# H6 register map
Vendor: Allwinner; Series: H6; File version: 0.1
CPU: CA53 0, little endian, MPU, no FPU, 0 interrupt priority bits
Registers are 32-bit, read-write, reset 0x0 unless marked. A register's access mark holds for its fields unless they carry their own. Offsets are from the block's base; [hi:lo] are bit positions; {n}, {i} and the like mark numbered series.

## RTC
Base 0x07000000
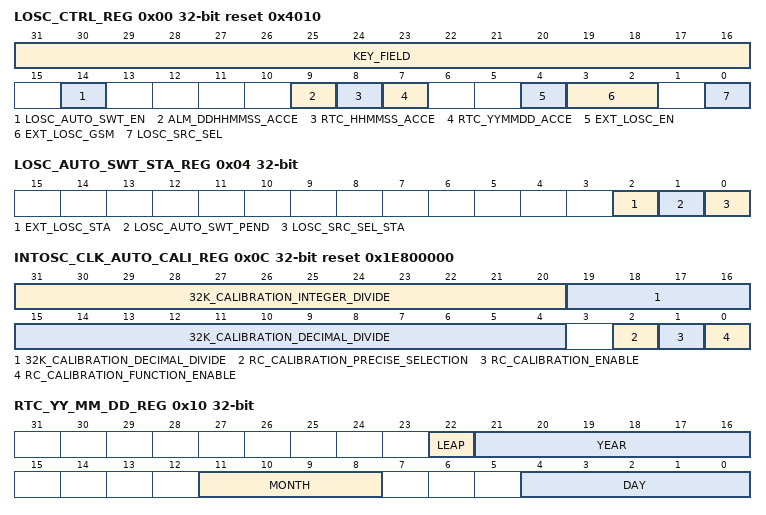
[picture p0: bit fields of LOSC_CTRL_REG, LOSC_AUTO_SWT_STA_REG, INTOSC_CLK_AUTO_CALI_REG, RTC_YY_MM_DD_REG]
0x00 LOSC_CTRL_REG reset 0x4010 — Low Oscillator Control Register
  [31:16] KEY_FIELD wo — Key Field. This field should be filled with 0x16AA, and then the bit 0 can be written with the new value.
  [14] LOSC_AUTO_SWT_EN — LOSC Auto Switch Enable. 0: Disable 1: Enable.
    0=Disable; 1=Enable
  [9] ALM_DDHHMMSS_ACCE — ALARM DD-HH-MM-SS access. After writing the Alarm 1 Week HH-MM-SS Register , this bit is set and it will be cleared until the real writing operation is finished.
  [8] RTC_HHMMSS_ACCE — RTC HH-MM-SS access. After writing the RTC HH-MM-SS Register , this bit is set and it will be cleared until the real writing operation is finished. After writing the RTC HH-MM-SS Register , the RTC HH-MM-SS Register will be refreshed for at most one second.
  [7] RTC_YYMMDD_ACCE — RTC YY-MM-DD access. After writing the RTC YY-MM-DD Register , this bit is set and it will be cleared until the real writing operation is finished. After writing the RTC YY-MM-DD Register , the RTC YY-MM-DD Register will be refreshed for at most one second.
  [4] EXT_LOSC_EN — External 32768Hz Crystal Enable. 0: Disable 1: Enable
    0=Disable; 1=Enable
  [3:2] EXT_LOSC_GSM — External 32768Hz Crystal GSM. 00: Low 01: / 10: / 11 High
    0=Low; 2=_slash_ (/ 11 High)
  [0] LOSC_SRC_SEL — LOSC Clock source Select. ` N ` is the value of Internal OSC Clock Prescalar Register . 0: InternalOSC /32/ N 1: External 32.768kHz OSC. (InternalOSC = 16MHz)
    0=InternalOSC /32/ N; 1=External 32.768kHz OSC. (InternalOSC = 16MHz)
0x04 LOSC_AUTO_SWT_STA_REG — LOSC Auto Switch Status Register
  [2] EXT_LOSC_STA ro — 0: External 32.768k OSC work normally. 1: External 32.768k OSC work abnormally.
    0=External_32_point_768k_OSC_work_normally (External 32.768k OSC work normally.); 1=External_32_point_768k_OSC_work_abnormally (External 32.768k OSC work abnormally.)
  [1] LOSC_AUTO_SWT_PEND write-1-clears — LOSC auto switch pending. 0: No effect 1: Auto switches pending Setting 1 to this bit will clear it.
    0=No_effect; 1=Auto switches pending Setting 1 to this bit will clear it
  [0] LOSC_SRC_SEL_STA ro — Checking LOSC Clock Source Status. ` N ` is the value of Internal OSC Clock Prescalar Register . 0: InternalOSC /32/ N 1: External 32.768kHz OSC (InternalOSC = 16MHz)
    0=InternalOSC /32/ N; 1=External 32.768kHz OSC (InternalOSC = 16MHz)
0x08 INTOSC_CLK_PRESCAL_REG reset 0xF — Internal OSC Clock Prescalar Register
  [15:0] INTOSC_CLK_PRESCAL — Internal OSC Clock Prescalar value N. 0x000: 1 0x001: 2 0x002: 3 ...... 0x1F: 32
    0=_1; 1=_2; 2=_3; 31=_32
0x0C INTOSC_CLK_AUTO_CALI_REG reset 0x1E800000 — Internal OSC Clock Auto Calibration Register
  [31:20] 32K_CALIBRATION_INTEGER_DIVIDE ro — 32K Calibration Integer Divide Factor.
  [19:4] 32K_CALIBRATION_DECIMAL_DIVIDE ro — 32K Calibration Decimal Divide Factor.
  [2] RC_CALIBRATION_PRECISE_SELECTION — RC Calibration Precise Selection 0: 1ms calibration precise 1: 16ms calibration precise
    0=1ms calibration precise; 1=16ms calibration precise
  [1] RC_CALIBRATION_ENABLE — RC calibration enable 0 : Close Calibration circuit 1 : Open Calibration circuit
  [0] RC_CALIBRATION_FUNCTION_ENABLE — RC calibration function enable 0 Normal RC 1 Calibrated RC
0x10 RTC_YY_MM_DD_REG (reset mask 0x400000) — RTC Year-Month-Day Register
  [22] LEAP — Leap Year. 0: Not 1: Leap year. This bit can not set by hardware. It should be set or cleared by software.
    0=Not; 1=Leap year. This bit can not set by hardware. It should be set or cleared by software.
  [21:16] YEAR — Year. Range from 0~63.
  [11:8] MONTH — Month. Range from 1~12.
  [4:0] DAY — Day. Range from 1~31.
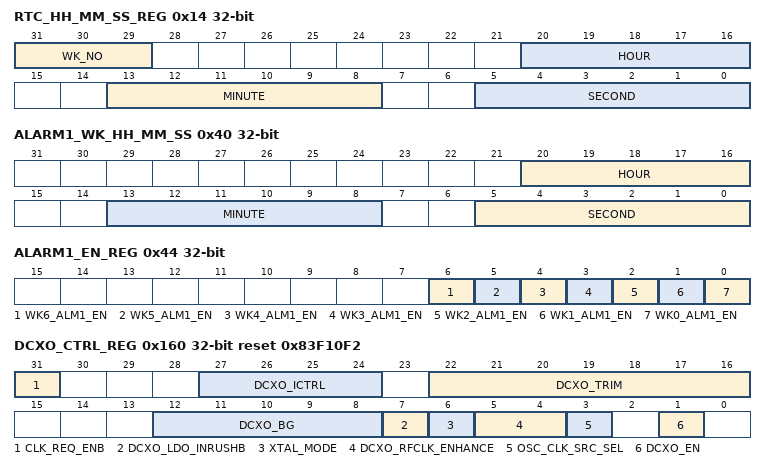
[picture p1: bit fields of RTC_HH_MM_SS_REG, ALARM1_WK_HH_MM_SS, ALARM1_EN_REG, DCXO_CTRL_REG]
0x14 RTC_HH_MM_SS_REG (reset mask 0xE0000000) — RTC Hour-Minute-Second Register
  [31:29] WK_NO — Week number. 000: Monday 001: Tuesday 010: Wednesday 011: Thursday 100: Friday 101: Saturday 110: Sunday 111: /
    0=Monday; 1=Tuesday; 2=Wednesday; 3=Thursday; 4=Friday; 5=Saturday; 6=Sunday
  [20:16] HOUR — Range from 0~23
  [13:8] MINUTE — Range from 0~59
  [5:0] SECOND — Range from 0~59
0x20 ALARM0_COUNTER_REG — Alarm 0 Counter Register
  [31:0] ALARM0_COUNTER — Alarm 0 Counter is based on second.
0x24 ALARM0_CUR_VLU_REG reset not defined — Alarm 0 Counter Current Value Register
  [31:0] ALARM0_CUR_VLU ro — Check Alarm 0 Counter Current Values.
0x28 ALARM0_ENABLE_REG — Alarm 0 Enable Register
  [0] ALM_0_EN — Alarm 0 Enable. If this bit is set to `1`, the valid bits of Alarm 0 Counter Register will down count to zero, and the alarm pending bit will be set to `1`. 0: Disable 1: Enable
    0=Disable; 1=Enable
0x2C ALARM0_IRQ_EN — Alarm 0 IRQ Enable Register
  [0] ALARM0_IRQ_EN — Alarm 0 IRQ Enable. 0: Disable 1: Enable
    0=Disable; 1=Enable
0x30 ALARM0_IRQ_STA_REG — Alarm 0 IRQ Status Register
  [0] ALARM0_IRQ_PEND write-1-clears — Alarm 0 IRQ Pending bit. 0: No effect 1: Pending, alarm 0 counter value is reached If alarm 0 irq enable is set to 1, the pending bit will be sent to the interrupt controller.
    0=No_effect; 1=Pending, alarm 0 counter value is reached If alarm 0 irq enable is set to 1, the pending bit will be sent to the interrupt controller
0x40 ALARM1_WK_HH_MM_SS reset not defined
  [20:16] HOUR — Range from 0~23.
  [13:8] MINUTE — Range from 0~59.
  [5:0] SECOND — Range from 0~59.
0x44 ALARM1_EN_REG
  [6] WK6_ALM1_EN — Week 6 (Sunday) Alarm 1 Enable. 0: Disable 1: Enable If this bit is set to `1`, only when the valid bits of Alarm 1 Week HH-MM-SS Register is equal to the bit[20:0] of RTC HH-MM-SS Register and the bit[31:29] of RTC HH-MM-SS Register is 6, the week 6 alarm irq pending bit will be set to `1`.
    0=Disable; 1=Enable If this bit is set to `1`, only when the valid bits of Alarm 1 Week HH-MM-SS Register is equal to the bit[20:0] of RTC HH-MM-SS Register and the bit[31:29] of RTC HH-MM-SS Register is 6, the week 6 alarm irq pending bit will be set to `1`
  [5] WK5_ALM1_EN — Week 5 (Saturday) Alarm 1 Enable. 0: Disable 1: Enable If this bit is set to `1`, only when the valid bits of Alarm 1 Week HH-MM-SS Register is equal to the bit[20:0] of RTC HH-MM-SS Register and the bit[31:29] of RTC HH-MM-SS Register is 5, the week 5 alarm irq pending bit will be set to `1`.
    0=Disable; 1=Enable If this bit is set to `1`, only when the valid bits of Alarm 1 Week HH-MM-SS Register is equal to the bit[20:0] of RTC HH-MM-SS Register and the bit[31:29] of RTC HH-MM-SS Register is 5, the week 5 alarm irq pending bit will be set to `1`
  [4] WK4_ALM1_EN — Week 4 (Friday) Alarm 1 Enable. 0: Disable 1: Enable If this bit is set to `1`, only when the valid bits of Alarm 1 Week HH-MM-SS Register is equal to the bit[20:0] of RTC HH-MM-SS Register and the register bit[31:29] of RTC HH-MM-SS Register is 4, the week 4 alarm irq pending bit will be set to `1`.
    0=Disable; 1=Enable If this bit is set to `1`, only when the valid bits of Alarm 1 Week HH-MM-SS Register is equal to the bit[20:0] of RTC HH-MM-SS Register and the register bit[31:29] of RTC HH-MM-SS Register is 4, the week 4 alarm irq pending bit will be set to `1`
  [3] WK3_ALM1_EN — Week 3 (Thursday) Alarm 1 Enable. 0: Disable 1: Enable If this bit is set to `1`, only when the valid bits of Alarm 1 Week HH-MM-SS Register is equal to the bit[20:0] of RTC HH-MM-SS Register and the bit[31:29] of RTC HH-MM-SS Register is 3, the week 3 alarm irq pending bit will be set to `1`.
    0=Disable; 1=Enable If this bit is set to `1`, only when the valid bits of Alarm 1 Week HH-MM-SS Register is equal to the bit[20:0] of RTC HH-MM-SS Register and the bit[31:29] of RTC HH-MM-SS Register is 3, the week 3 alarm irq pending bit will be set to `1`
  [2] WK2_ALM1_EN — Week 2 (Wednesday) Alarm 1 Enable. 0: Disable 1: Enable If this bit is set to `1`, only when the valid bits of Alarm 1 Week HH-MM-SS Register is equal to the bit[20:0] of RTC HH-MM-SS Register and the bit[31:29] of RTC HH-MM-SS Register is 2, the week 2 alarm irq pending bit will be set to `1`.
    0=Disable; 1=Enable If this bit is set to `1`, only when the valid bits of Alarm 1 Week HH-MM-SS Register is equal to the bit[20:0] of RTC HH-MM-SS Register and the bit[31:29] of RTC HH-MM-SS Register is 2, the week 2 alarm irq pending bit will be set to `1`
  [1] WK1_ALM1_EN — Week 1 (Tuesday) Alarm 1 Enable. 0: Disable 1: Enable If this bit is set to `1`, only when the valid bits of Alarm 1 Week HH-MM-SS Register is equal to the bit[20:0] of RTC HH-MM-SS Register and the bit[31:29] of RTC HH-MM-SS Register is 1, the week 1 alarm irq pending bit will be set to `1`.
    0=Disable; 1=Enable If this bit is set to `1`, only when the valid bits of Alarm 1 Week HH-MM-SS Register is equal to the bit[20:0] of RTC HH-MM-SS Register and the bit[31:29] of RTC HH-MM-SS Register is 1, the week 1 alarm irq pending bit will be set to `1`
  [0] WK0_ALM1_EN — Week 0 (Monday) Alarm 1 Enable. 0: Disable 1: Enable If this bit is set to `1`, only when the valid bits of Alarm 1 Week HH-MM-SS Register is equal to the bit[20:0] of RTC HH-MM-SS Register and the bit[31:29] of RTC HH-MM-SS Register is 0, the week 0 alarm irq pending bit will be set to `1`.
    0=Disable; 1=Enable If this bit is set to `1`, only when the valid bits of Alarm 1 Week HH-MM-SS Register is equal to the bit[20:0] of RTC HH-MM-SS Register and the bit[31:29] of RTC HH-MM-SS Register is 0, the week 0 alarm irq pending bit will be set to `1`
0x48 ALARM1_IRQ_EN — Alarm 1 IRQ Enable Register
  [0] ALARM1_IRQ_EN — Alarm 1 IRQ Enable. 0: Disable 1: Enable
    0=Disable; 1=Enable
0x4C ALARM1_IRQ_STA_REG — Alarm 1 IRQ Status Register
  [0] ALARM1_WEEK_IRQ_PEND write-1-clears — Alarm 1 Week (0/1/2/3/4/5/6) IRQ Pending. 0: No effect 1: Pending, week counter value is reached If alarm 1 week irq enable is set to 1, the pending bit will be sent to the interrupt controller.
    0=No_effect; 1=Pending, week counter value is reached If alarm 1 week irq enable is set to 1, the pending bit will be sent to the interrupt controller
0x50 ALARM_CONFIG_REG — Alarm Configuration Register
  [0] ALARM_WAKEUP — Configuration of alarm wake up output. 0: Disable alarm wake up output 1: Enable alarm wake up output
    0=Disable alarm wake up output; 1=Enable alarm wake up output
0x60 LOSC_OUT_GATING_REG — LOSC Output Gating Register
  [0] LOSC_OUT_GATING — Configuration of LOSC output, and without LOSC output by default. 0: Enable LOSC output gating 1: Disable LOSC output gating
    0=Enable LOSC output gating; 1=Disable LOSC output gating
{0x100+4i} GP_DATA_REGN[{i}] (i=0..7) — GP_DATA_REGN[{i}]
  [31:0] GP_DATA — Data [31:0].
0x160 DCXO_CTRL_REG reset 0x83F10F2 (reset mask 0x8F7F1FF2)
  [31] CLK_REQ_ENB — 0: Enable DCXO wake up function 1: Disable DCXO wake up function
    0=Enable DCXO wake up function; 1=Disable DCXO wake up function
  [27:24] DCXO_ICTRL — DCXO current control value
  [22:16] DCXO_TRIM — DCXO cap array value cap cell is 55fF
  [12:8] DCXO_BG — DCXO bandgap output voltage
  [7] DCXO_LDO_INRUSHB — DCXO LDO driving capacity signal, active high
  [6] XTAL_MODE — Xtal mode enable signal, active high 0: for external clk input mode. 1: for normal mode.
    0=for external clk input mode; 1=for normal mode
  [5:4] DCXO_RFCLK_ENHANCE — DCXO rfclk enhance Enhance driving capacity of output OUT_RF_REFCLK, 0x0 for 5pF, 0x1 for 10pF, 0x2 for 15pF, 0x3 for 20pF
  [3] OSC_CLK_SRC_SEL — OSC_CLK_SRC_SEL.(Pad select) High frequency clock source select. 0: XO24M 1: DCXO
    0=XO24M; 1=DCXO
  [1] DCXO_EN — DCXO enable. 1: Enable 0: Disable
    1=Enable; 0=Disable
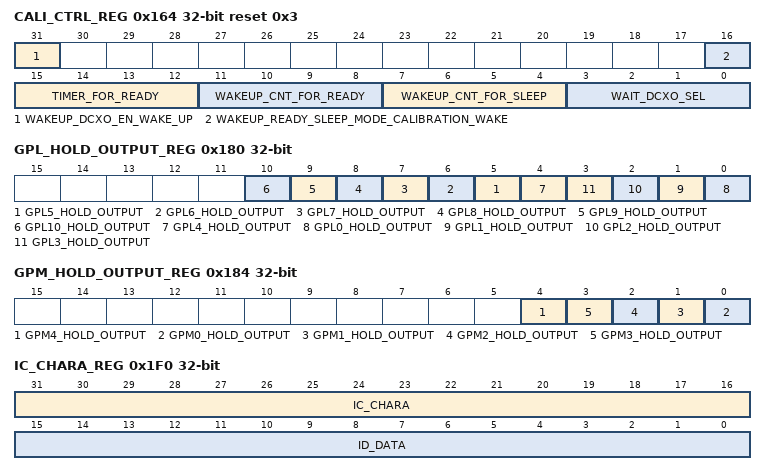
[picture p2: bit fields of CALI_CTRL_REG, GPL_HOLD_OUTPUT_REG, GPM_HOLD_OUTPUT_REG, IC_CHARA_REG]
0x164 CALI_CTRL_REG reset 0x3 — Calibration Control Register
  [31] WAKEUP_DCXO_EN_WAKE_UP — WAKEUP_DCXO_EN Wake up DCXO circuit enable.
  [16] WAKEUP_READY_SLEEP_MODE_CALIBRATION_WAKE — WAKEUP_READY_SLEEP_MODE Calibration wake up ready sleep mode 0: Disable 1: Enable
    0=Disable; 1=Enable
  [15:12] TIMER_FOR_READY — TIMER FOR READY SLEEP Total timer for ready sleep 0000: 15s 0001: 30s 0010: 45s 0011: 60s 0100: 90s 0101: 120s 0110: 150s Others: /
    0=_15s; 1=_30s; 2=_45s; 3=_60s; 4=_90s; 5=_120s; 6=150s Others: /
  [11:8] WAKEUP_CNT_FOR_READY — WAKEUP_CNT FOR READY SLEEP Wake up counter for ready sleep 0000: 250ms 0001: 500ms 0010: 750ms 0011: 1s 0100: 1.25s 0101: 1.5s 0110: 1.75s 0111: 2s 1000: 2.25s 1001: 2.5s 1010: 2.75s 1011: 3s 1100: 3.25s 1101: 3.5s 1110: 3.75s 1111: 4s
    0=_250ms; 1=_500ms; 2=_750ms; 3=_1s; 4=_1_point_25s (1.25s); 5=_1_point_5s (1.5s); 6=_1_point_75s (1.75s); 7=_2s; 8=_2_point_25s (2.25s); 9=_2_point_5s (2.5s); 10=_2_point_75s (2.75s); 11=_3s; 12=_3_point_25s (3.25s); 13=_3_point_5s (3.5s); 14=_3_point_75s (3.75s); 15=_4s
  [7:4] WAKEUP_CNT_FOR_SLEEP — WAKEUP_CNT FOR SLEEP Wake up counter for sleep 0000: 250ms 0001: 500ms 0010: 1s 0011: 2s 0100: 3s 0101: 4s 0110: 5s 0111: 6s 1000: 7s 1001: 8s 1010: 9s 1011: 10s 1100: 11s 1101: 12s 1110: 30s 1111: 60s
    0=_250ms; 1=_500ms; {v}=_{v-1}s (v=2..13); 14=_30s; 15=_60s
  [3:0] WAIT_DCXO_SEL — WAIT DCXO SEL Select for DCXO active after DCXO enable 0000:1ms 0001:2ms 0010:3ms 0011:4ms ... 1111: 16ms
    15=_16ms
0x180 GPL_HOLD_OUTPUT_REG — GPL Hold Output Register
  [all] fields
    0=Hold_disable; 1=Hold_enable
  [n] GPL{n}_HOLD_OUTPUT (n=5..10) — Hold the output of GPIOL{n} when the power of system is changing. The output must be low level (0) or high level (1) or High-Z; any other outputs may not hold on. 0: Hold disable 1: Hold enable
  [4] GPL4_HOLD_OUTPUT — Hold the output of GPIOL4 when the power of system is changing. The output must be low level (0) or high level (1) or High-Z; any other output may not hold on. 0: Hold disable 1: Hold enable
  [n] GPL{n}_HOLD_OUTPUT (n=0..3) — Hold the output of GPIOL{n} when the power of system is changing. The output must be low level (0) or high level (1) or High-Z; any other outputs may not hold on. 0: Hold disable 1: Hold enable
0x184 GPM_HOLD_OUTPUT_REG
  [all] fields
    0=Hold_disable; 1=Hold_enable
  [4] GPM4_HOLD_OUTPUT — Hold the output of GPIOL4 when system`s power is changing. The outputs must be low level (0) or high level (1) or High-Z; any other output may not hold on. 0: Hold disable 1: Hold enable
  [n] GPM{n}_HOLD_OUTPUT (n=0..3) — Hold the output of GPIOL{n} when system`s power is changing. The output must be low level (0) or high level (1) or High-Z; any other outputs may not hold on. 0: Hold disable 1: Hold enable
0x188 RTC_PWR_MODE_SEL_REG reset 0x1 — RTC POWER MODE SELECT Register
  [0] RTC_POW_MOD_SELECT — VCC-RTC POWER MODE SELECT. 0: 3.3V 1:1.8V
    0=_3_point_3V (3.3V 1:1.8V)
0x190 RTC_VIO_REG reset 0x4
  [2:0] RTC_VIO_REGU — These bits are useful for regulating the RTC-VIO from 0.6V to 1.3V. 000: 1.0V 001: 0.6V 010: 0.7V 011: 0.8V 100: 0.9V 101: 1.1V 110: 1.2V 111: 1.3V
    0=_1_point_0V (1.0V); 1=_0_point_6V (0.6V); 2=_0_point_7V (0.7V); 3=_0_point_8V (0.8V); 4=_0_point_9V (0.9V); 5=_1_point_1V (1.1V); 6=_1_point_2V (1.2V); 7=_1_point_3V (1.3V)
0x1B8 BOOT_CPU_HP_FLAG_REG — Boot CPU Hot Plug Flag Register
  [31:0] BOOT — Boot CPU software flag when acting from hot plug.
0x1BC CPU_SOFT_ENT_REG
  [31:0] BOOT — Boot CPU software entry register when acting from hot plug or Non-boot CPU software entry register.
0x1F0 IC_CHARA_REG — IC Characteristic Register
  [31:16] IC_CHARA — Key Field.
  [15:0] ID_DATA
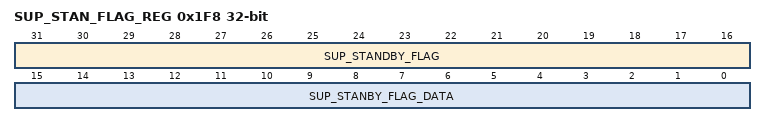
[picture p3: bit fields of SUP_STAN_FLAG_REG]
0x1F8 SUP_STAN_FLAG_REG — Super Standby Flag Register
  [31:16] SUP_STANDBY_FLAG — Key Field. Any value can be written and read back in the key field, but if the values are not appropriate, the lower 16 bits will not change in this register. Only fellow the appropriate process, the super standby flag can be written in the lower 16 bits. Refer to Description and Diagram.
  [15:0] SUP_STANBY_FLAG_DATA — Refer to Description and Diagram
0x1FC CPU_SOFT_ENT_REG1 — CPU Software Entry Register 1
  [31:0] CPU — software entry register when acting from super standby.
0x210 CRY_CONFIG_REG — Crypto Configuration Register
  [15:0] KEY_FIELD
0x214 CRY_KEY_REG — Crypto Key Register
  [31:0] CRY_KEY — Crypto Key
0x218 CRY_EN_REG — Crypto Enable Register
  [0] CRY_EN — Crypto Enable
